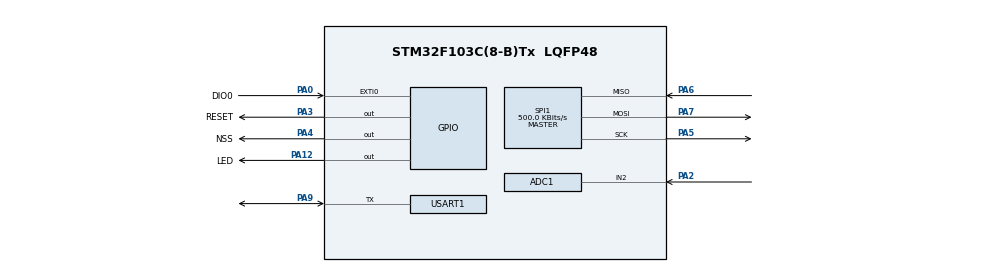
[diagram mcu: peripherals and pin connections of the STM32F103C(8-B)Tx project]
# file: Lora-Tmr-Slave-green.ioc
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ADC1.Channel-0\#ChannelRegularConversion=ADC_CHANNEL_2
ADC1.NbrOfConversionFlag=1
ADC1.Rank-0\#ChannelRegularConversion=1
ADC1.SamplingTime-0\#ChannelRegularConversion=ADC_SAMPLETIME_1CYCLE_5
ADC1.master=1
Mcu.Family=STM32F1
Mcu.Name=STM32F103C(8-B)Tx
Mcu.Package=LQFP48
NVIC.EXTI0_IRQn=true\:0\:0\:false\:false\:true\:true\:true\:true
NVIC.PriorityGroup=NVIC_PRIORITYGROUP_4
PA0-WKUP.GPIO_Label=DIO0
PA0-WKUP.GPIO_PuPd=GPIO_PULLDOWN
PA0-WKUP.Signal=GPXTI0
PA12.GPIO_Label=LED
PA12.GPIO_ModeDefaultOutputPP=GPIO_MODE_OUTPUT_OD
PA12.GPIO_PuPd=GPIO_NOPULL
PA12.PinState=GPIO_PIN_SET
PA12.Signal=GPIO_Output
PA13.Mode=Serial_Wire
PA13.Signal=SYS_JTMS-SWDIO
PA14.Mode=Serial_Wire
PA14.Signal=SYS_JTCK-SWCLK
PA2.Signal=ADCx_IN2
PA3.GPIO_Label=RESET
PA3.PinState=GPIO_PIN_SET
PA3.Signal=GPIO_Output
PA4.GPIO_Label=NSS
PA4.GPIO_PuPd=GPIO_PULLUP
PA4.PinState=GPIO_PIN_SET
PA4.Signal=GPIO_Output
PA5.Mode=Full_Duplex_Master
PA5.Signal=SPI1_SCK
PA6.Mode=Full_Duplex_Master
PA6.Signal=SPI1_MISO
PA7.Mode=Full_Duplex_Master
PA7.Signal=SPI1_MOSI
PA9.Mode=Half_duplex(single_wire_mode)
PA9.Signal=USART1_TX
ProjectManager.HeapSize=0x200
ProjectManager.StackSize=0x400
ProjectManager.TargetToolchain=STM32CubeIDE
RCC.APB1Freq_Value=8000000
RCC.APB2Freq_Value=8000000
SH.ADCx_IN2.0=ADC1_IN2,IN2
SPI1.BaudRatePrescaler=SPI_BAUDRATEPRESCALER_16
SPI1.CalculateBaudRate=500.0 KBits/s
SPI1.Direction=SPI_DIRECTION_2LINES
SPI1.Mode=SPI_MODE_MASTER
SPI1.VirtualType=VM_MASTER
USART1.VirtualMode=VM_ASYNC
VP_CRC_VS_CRC.Mode=CRC_Activate
board=custom

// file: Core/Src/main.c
/* USER CODE BEGIN Header */
/**
  ******************************************************************************
  * @file           : main.c
  * @brief          : Main program body
  ******************************************************************************
  * @attention
  *
  * Copyright (c) 2022 STMicroelectronics.
  * All rights reserved.
  *
  * This software is licensed under terms that can be found in the LICENSE file
  * in the root directory of this software component.
  * If no LICENSE file comes with this software, it is provided AS-IS.
  *
  ******************************************************************************
  */
/* USER CODE END Header */
#include "main.h"
#include "adc.h"
#include "crc.h"
#include "spi.h"
#include "usart.h"
#include "gpio.h"

/* USER CODE BEGIN Includes */

	#include "LoRa-Contact_SM.h"

/* USER CODE END Includes */

void SystemClock_Config(void);

int main(void)
{

  /* MCU Configuration--------------------------------------------------------*/

  /* Reset of all peripherals, Initializes the Flash interface and the Systick. */
  HAL_Init();

  /* Configure the system clock */
  SystemClock_Config();

  /* Initialize all configured peripherals */
  MX_GPIO_Init();
  MX_ADC1_Init();
  MX_SPI1_Init();
  MX_CRC_Init();
  MX_USART1_UART_Init();
  /* USER CODE BEGIN 2 */

  	  LoRa_Slave_Init();

  /* USER CODE END 2 */

  /* Infinite loop */
  /* USER CODE BEGIN WHILE */
  while (1)
  {
	  LoRa_Slave_Main();

    /* USER CODE END WHILE */

  }
}

void SystemClock_Config(void)
{
  RCC_OscInitTypeDef RCC_OscInitStruct = {0};
  RCC_ClkInitTypeDef RCC_ClkInitStruct = {0};
  RCC_PeriphCLKInitTypeDef PeriphClkInit = {0};

  /** Initializes the RCC Oscillators according to the specified parameters
  * in the RCC_OscInitTypeDef structure.
  */
  RCC_OscInitStruct.OscillatorType = RCC_OSCILLATORTYPE_HSI;
  RCC_OscInitStruct.HSIState = RCC_HSI_ON;
  RCC_OscInitStruct.HSICalibrationValue = RCC_HSICALIBRATION_DEFAULT;
  RCC_OscInitStruct.PLL.PLLState = RCC_PLL_NONE;
  if (HAL_RCC_OscConfig(&RCC_OscInitStruct) != HAL_OK)
  {
    Error_Handler();
  }

  /** Initializes the CPU, AHB and APB buses clocks
  */
  RCC_ClkInitStruct.ClockType = RCC_CLOCKTYPE_HCLK|RCC_CLOCKTYPE_SYSCLK
                              |RCC_CLOCKTYPE_PCLK1|RCC_CLOCKTYPE_PCLK2;
  RCC_ClkInitStruct.SYSCLKSource = RCC_SYSCLKSOURCE_HSI;
  RCC_ClkInitStruct.AHBCLKDivider = RCC_SYSCLK_DIV1;
  RCC_ClkInitStruct.APB1CLKDivider = RCC_HCLK_DIV1;
  RCC_ClkInitStruct.APB2CLKDivider = RCC_HCLK_DIV1;

  if (HAL_RCC_ClockConfig(&RCC_ClkInitStruct, FLASH_LATENCY_0) != HAL_OK)
  {
    Error_Handler();
  }
  PeriphClkInit.PeriphClockSelection = RCC_PERIPHCLK_ADC;
  PeriphClkInit.AdcClockSelection = RCC_ADCPCLK2_DIV2;
  if (HAL_RCCEx_PeriphCLKConfig(&PeriphClkInit) != HAL_OK)
  {
    Error_Handler();
  }
}

void Error_Handler(void)
{
  __disable_irq();
  while (1)
  {
  }
}
